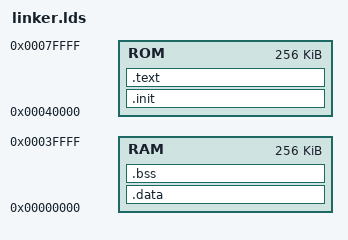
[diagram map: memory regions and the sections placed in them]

ENTRY(_start16)

MEMORY
{
        RAM : ORIGIN = 0x00000000, LENGTH = 256K
        ROM : ORIGIN = 0x00040000, LENGTH = 256K
}

SECTIONS
{
        /**********************************************************************
         *                                                                    *
         **********************************************************************/
        .init : AT(ORIGIN(ROM))
        {
                *(.init16)
                . = ALIGN(0x10);
        } > ROM
        /**********************************************************************
         *                                                                    *
         **********************************************************************/
        .text ALIGN(0x20) :
        {
                _stext = .;
                . = ALIGN(0x10);
                *(.startup)
                *(.text)
                *(.text.*)
                *(.rodata)
                *(.rodata.*)
                *(.gnu.linkonce.t.*)
                *(.gnu.linkonce.r.*)
                . = ALIGN(0x10);
                _etext = .;
        } > ROM
        /**********************************************************************
         *                                                                    *
         **********************************************************************/
        .data : AT(_etext)
        {
                _sdata = .;
                . = ALIGN(0x10);
                *(.data)
                *(.data.*)
                *(.gnu.linkonce.d.*)
                . = ALIGN(0x10);
                _edata = .;
        } > RAM
        /**********************************************************************
         *                                                                    *
         **********************************************************************/
        .bss ADDR(.data) + SIZEOF(.data) (NOLOAD) :
        {
                . = ALIGN(0x10);
                _sbss = .;
                *(.bss)
                *(.bss.*)
                *(COMMON)
                *(.gnu.linkonce.b.*)
                . = ALIGN(0x10);
                _ebss = .;
        } > RAM
        /**********************************************************************
         *                                                                    *
         **********************************************************************/
        /DISCARD/ :
        {
                *(.comment)
                *(.eh_frame)
        }
}

